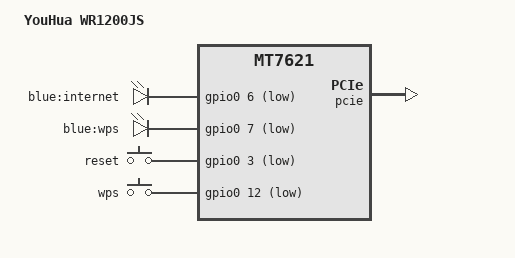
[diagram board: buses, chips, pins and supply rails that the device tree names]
/dts-v1/;

#include "mt7621.dtsi"
#include <dt-bindings/input/input.h>
#include "mt7621-spi-16m-layout.dtsi"
#include "mt7621-raeth-gmac2.dtsi"
#include "mt7621-pinctrl-default-gpio.dtsi"

/ {
	compatible = "mediatek,mt7621-soc";
	model = "YouHua WR1200JS";

	chosen {
		bootargs = "console=ttyS0,57600";
	};

	leds {
		compatible = "gpio-leds";

		internet {
			label = "blue:internet";
			gpios = <&gpio0 6 GPIO_ACTIVE_LOW>;
		};

		led_wps: wps {
			label = "blue:wps";
			gpios = <&gpio0 7 GPIO_ACTIVE_LOW>;
		};
	};

	gpio-keys-polled {
		compatible = "gpio-keys-polled";
		#address-cells = <1>;
		#size-cells = <0>;
		poll-interval = <20>;

		reset {
			label = "reset";
			gpios = <&gpio0 3 GPIO_ACTIVE_LOW>;
			linux,code = <KEY_RESTART>;
		};

		wps {
			label = "wps";
			gpios = <&gpio0 12 GPIO_ACTIVE_LOW>;
			linux,code = <KEY_WPS_BUTTON>;
		};

	};
};

&pcie {
	status = "okay";
};
